VERSION ""

NS_ :

BS_:

BU_: XXX

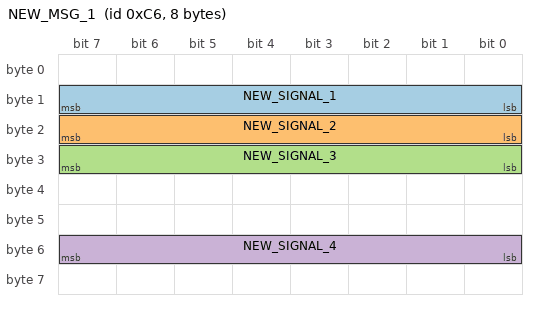
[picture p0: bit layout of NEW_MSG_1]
BO_ 198 NEW_MSG_1: 8 XXX
 SG_ NEW_SIGNAL_1 : 15|8@0+ (1,0) [0|255] "" XXX
 SG_ NEW_SIGNAL_2 : 23|8@0+ (1,0) [0|255] "" XXX
 SG_ NEW_SIGNAL_3 : 31|8@0+ (1,0) [0|255] "" XXX
 SG_ NEW_SIGNAL_4 : 55|8@0+ (1,0) [0|255] "" XXX

BO_ 535 NEW_MSG_2: 8 XXX
 SG_ NEW_SIGNAL_1 : 39|8@0+ (1,0) [0|255] "" XXX

BO_ 1642 NEW_MSG_3: 8 XXX
 SG_ NEW_SIGNAL_1 : 31|8@0+ (1,0) [0|255] "" XXX

BO_ 390 NEW_MSG_4: 8 XXX
 SG_ Accelerator : 7|8@0+ (1,0) [0|255] "" XXX
